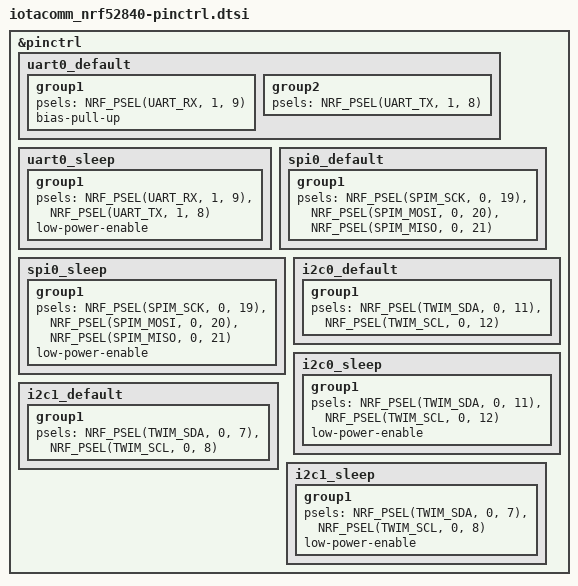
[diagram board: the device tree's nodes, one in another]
/*
 * Copyright (c) 2023 CONNECTED DEVELOPMENT, A DIVISION OF
 *   EXPONENTIAL TECHNOLOGY GROUP.
 *
 * Copyright (c) 2017 Linaro Limited
 * SPDX-License-Identifier: Apache-2.0
 */

/*
 * Pin definitions for the IotaComm board.
 */

&pinctrl {
	uart0_default: uart0_default {
		group1 {
			psels = <NRF_PSEL(UART_RX, 1, 9)>;
			bias-pull-up;
		};
		group2 {
			psels = <NRF_PSEL(UART_TX, 1, 8)>;
		};
	};

	uart0_sleep: uart0_sleep {
		group1 {
			psels = <NRF_PSEL(UART_RX, 1, 9)>,
				<NRF_PSEL(UART_TX, 1, 8)>;
			low-power-enable;
		};
	};

	spi0_default: spi0_default {
		group1 {
			psels = <NRF_PSEL(SPIM_SCK, 0, 19)>,
				<NRF_PSEL(SPIM_MOSI, 0, 20)>,
				<NRF_PSEL(SPIM_MISO, 0, 21)>;
		};
	};

	spi0_sleep: spi0_sleep {
		group1 {
			psels = <NRF_PSEL(SPIM_SCK, 0, 19)>,
				<NRF_PSEL(SPIM_MOSI, 0, 20)>,
				<NRF_PSEL(SPIM_MISO, 0, 21)>;
			low-power-enable;
		};
	};

	i2c0_default: i2c0_default {
		group1 {
			psels = <NRF_PSEL(TWIM_SDA, 0, 11)>,
				<NRF_PSEL(TWIM_SCL, 0, 12)>;
		};
	};

	i2c0_sleep: i2c0_sleep {
		group1 {
			psels = <NRF_PSEL(TWIM_SDA, 0, 11)>,
				<NRF_PSEL(TWIM_SCL, 0, 12)>;
			low-power-enable;
		};
	};

	i2c1_default: i2c1_default {
		group1 {
			psels = <NRF_PSEL(TWIM_SDA, 0, 7)>,
				<NRF_PSEL(TWIM_SCL, 0, 8)>;
		};
	};

	i2c1_sleep: i2c1_sleep {
		group1 {
			psels = <NRF_PSEL(TWIM_SDA, 0, 7)>,
				<NRF_PSEL(TWIM_SCL, 0, 8)>;
			low-power-enable;
		};
	};
};
